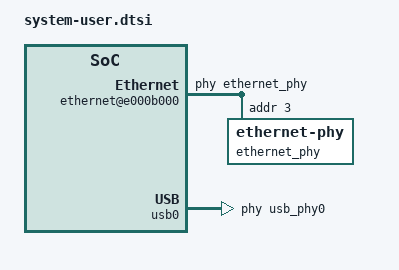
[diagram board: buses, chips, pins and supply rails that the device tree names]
/include/ "system-conf.dtsi"
/ {
	amba {

		ethernet@e000b000 {
			phy-handle = <&ethernet_phy>;
			ethernet_phy: ethernet-phy@3{
                rxc-skew-ps = <1860>;
                rxdv-skew-ps = <420>;
                rxd0-skew-ps = <420>;
                rxd1-skew-ps = <420>;
                rxd2-skew-ps = <420>;
                rxd3-skew-ps = <420>;

                txc-skew-ps = <1860>;
                txen-skew-ps = <420>;
                txd0-skew-ps = <420>;
                txd1-skew-ps = <420>;
                txd2-skew-ps = <420>;
                txd3-skew-ps = <420>;
   				reg = <3>;
			};
		};
	};
        usb_phy0: phy0 {
                compatible = "ulpi-phy";
                #phy-cells = <0>;
                reg = <0xe0002000 0x1000>;
                view-port = <0x170>;
                drv-vbus;
        };
};

&usb0 {
        usb-phy = <&usb_phy0>;
};
